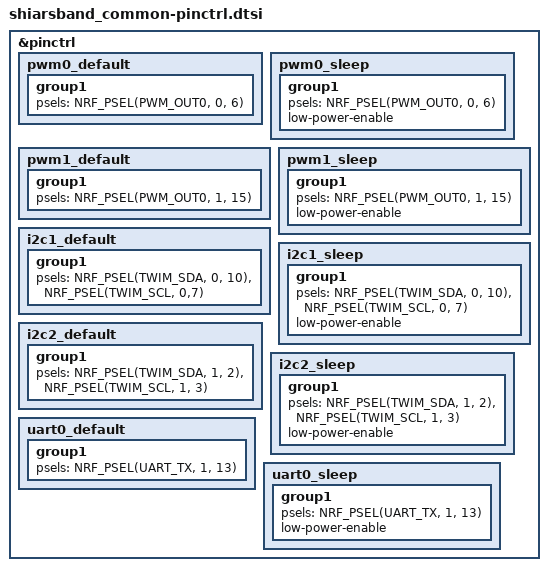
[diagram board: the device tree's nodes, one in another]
/*
 * Copyright (c) 2022 Nordic Semiconductor
 * SPDX-License-Identifier: Apache-2.0
 */


 &pinctrl {
	/*Pin: Display Back Light */
		pwm0_default: pwm0_default {
			group1 {
				psels = <NRF_PSEL(PWM_OUT0, 0, 6)>;
			};
		};
	
		pwm0_sleep: pwm0_sleep {
			group1 {
				psels = <NRF_PSEL(PWM_OUT0, 0, 6)>;
				low-power-enable;
			};
		};
	/*Pin: Vibrator Motor driver */
		pwm1_default: pwm1_default {
			group1 {
				psels = <NRF_PSEL(PWM_OUT0, 1, 15)>;
			};
		};
	
		pwm1_sleep: pwm1_sleep {
			group1 {
				psels = <NRF_PSEL(PWM_OUT0, 1, 15)>;
				low-power-enable;
			};
		};
	/*Pin:  Sensor */
		i2c1_default: i2c1_default {
			group1 {
				psels = <NRF_PSEL(TWIM_SDA, 0, 10)>,
					<NRF_PSEL(TWIM_SCL, 0,7)>;
			};
		};
	
		i2c1_sleep: i2c1_sleep {
			group1 {
				psels = <NRF_PSEL(TWIM_SDA, 0, 10)>,
					<NRF_PSEL(TWIM_SCL, 0, 7)>;
				low-power-enable;
			};
		};
	/*Pin: tOUCH Sensors */
		i2c2_default: i2c2_default {
			group1 {
				psels = <NRF_PSEL(TWIM_SDA, 1, 2)>,
					<NRF_PSEL(TWIM_SCL, 1, 3)>;
			};
		};
	
		i2c2_sleep: i2c2_sleep {
			group1 {
				psels = <NRF_PSEL(TWIM_SDA, 1, 2)>,
					<NRF_PSEL(TWIM_SCL, 1, 3)>;
				low-power-enable;
			};
		};
	/*Pin: Display */
		uart0_default: uart0_default {
			group1 {
				psels = <NRF_PSEL(UART_TX, 1, 13)>;
			};
		};
	
		uart0_sleep: uart0_sleep {
			group1 {
				psels = <NRF_PSEL(UART_TX, 1, 13)>;
				low-power-enable;
			};
		};
		
	};
	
